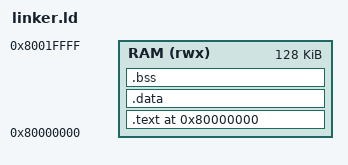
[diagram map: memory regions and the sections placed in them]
ENTRY(_start)

MEMORY
{
    RAM (rwx) : ORIGIN = 0x80000000, LENGTH = 128K
}

SECTIONS
{
    . = 0x80000000;
    .text : {
        *(.text.entry)
        *(.text)
    } > RAM

    .data : {
        *(.data)
    } > RAM

    .bss : {
        *(.bss)
    } > RAM
}
